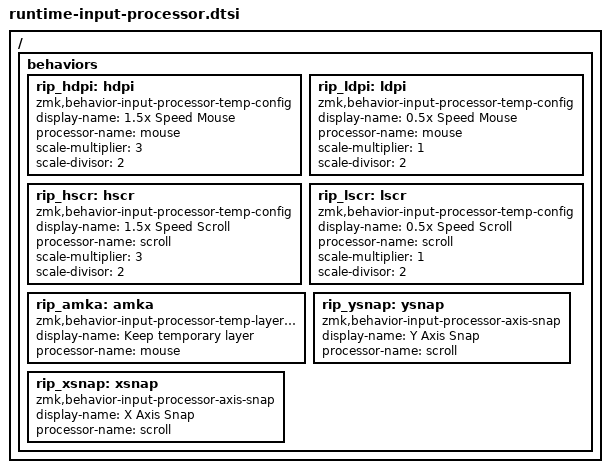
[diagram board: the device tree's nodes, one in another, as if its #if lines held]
/*
* Copyright (c) 2026 The ZMK Contributors
* SPDX-License-Identifier: MIT
*
* Common Runtime Input Processor Configurations
*
* This file provides pre-configured runtime input processors that can be easily
* included and used in keyboard configurations. Users can override these or
* create their own custom processors.
*/

#include <dt-bindings/zmk/behaviors.h>

/ {
	behaviors {
		// High DPI
#if ZMK_BEHAVIOR_OMIT(RIP)
		/omit-if-no-ref/
		#endif
		rip_hdpi: hdpi {
			compatible = "zmk,behavior-input-processor-temp-config";
			display-name = "1.5x Speed Mouse";
			processor-name = "mouse";
			// 1.5x scaling
			scale-multiplier = <3>;
			scale-divisor = <2>;

			#binding-cells = <0>;
		};

		// Low DPI
    #if ZMK_BEHAVIOR_OMIT(RIP)
		/omit-if-no-ref/
		#endif
		rip_ldpi: ldpi {
			compatible = "zmk,behavior-input-processor-temp-config";
			display-name = "0.5x Speed Mouse";
			processor-name = "mouse";
			// x0.5 scaling
			scale-multiplier = <1>;
			scale-divisor = <2>;

			#binding-cells = <0>;
		};

		// High Speed Scroll
    #if ZMK_BEHAVIOR_OMIT(RIP)
		/omit-if-no-ref/
		#endif
		rip_hscr: hscr {
			compatible = "zmk,behavior-input-processor-temp-config";
			display-name = "1.5x Speed Scroll";
			processor-name = "scroll";

			scale-multiplier = <3>;
			scale-divisor = <2>;

			#binding-cells = <0>;
		};

		// Low Speed Scroll
    #if ZMK_BEHAVIOR_OMIT(RIP)
		/omit-if-no-ref/
		#endif
		rip_lscr: lscr {
			compatible = "zmk,behavior-input-processor-temp-config";
			display-name = "0.5x Speed Scroll";
			processor-name = "scroll";
			scale-multiplier = <1>;
			scale-divisor = <2>;

			#binding-cells = <0>;
		};

        #if ZMK_BEHAVIOR_OMIT(RIP)
		/omit-if-no-ref/
		#endif
		rip_amka: amka {
			compatible = "zmk,behavior-input-processor-temp-layer-keep-active";
			display-name = "Keep temporary layer";
			processor-name = "mouse";
			#binding-cells = <0>;
		};

		// Axis Snap - Y Axis (for vertical scrolling)
        #if ZMK_BEHAVIOR_OMIT(RIP)
		/omit-if-no-ref/
		#endif
		rip_ysnap: ysnap {
			compatible = "zmk,behavior-input-processor-axis-snap";
			display-name = "Y Axis Snap";
			processor-name = "scroll";

			#binding-cells = <2>;
		};

		// Axis Snap - X Axis (for horizontal scrolling)
        #if ZMK_BEHAVIOR_OMIT(RIP)
		/omit-if-no-ref/
		#endif
		rip_xsnap: xsnap {
			compatible = "zmk,behavior-input-processor-axis-snap";
			display-name = "X Axis Snap";
			processor-name = "scroll";

			#binding-cells = <2>;
		};
	};
};
